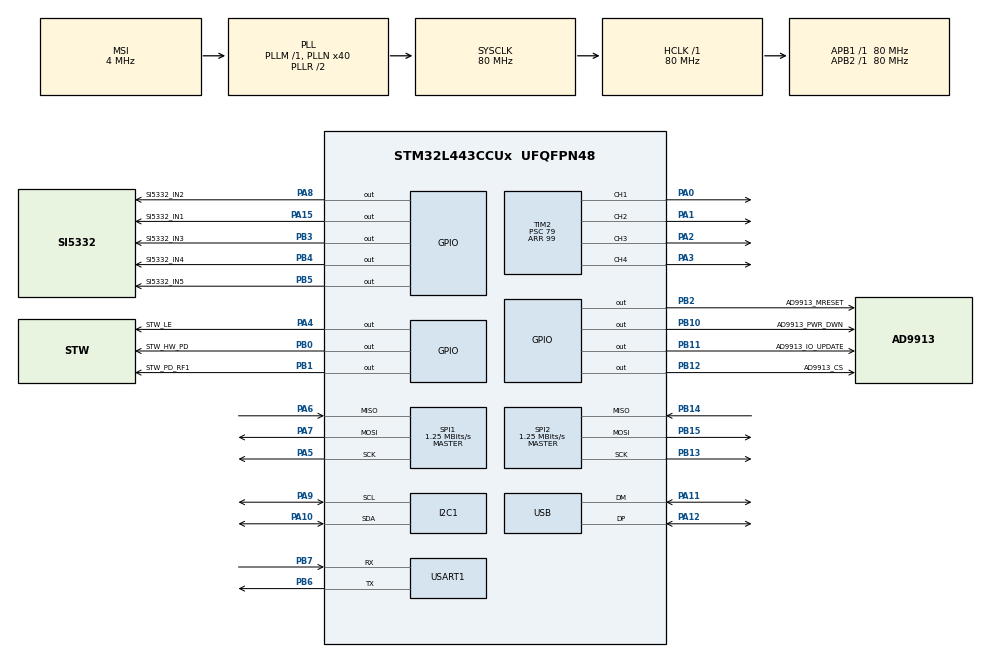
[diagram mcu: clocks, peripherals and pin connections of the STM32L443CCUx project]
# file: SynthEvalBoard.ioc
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FREERTOS.MEMORY_ALLOCATION=1
FREERTOS.Tasks01=defaultTask,0,4096,StartDefaultTask,Default,NULL,Static,defaultTaskBuffer,defaultTaskControlBlock
Mcu.Family=STM32L4
Mcu.Name=STM32L443CCUx
Mcu.Package=UFQFPN48
NVIC.PriorityGroup=NVIC_PRIORITYGROUP_4
NVIC.TIM7_IRQn=true\:0\:0\:false\:false\:true\:false\:false\:true
NVIC.TimeBase=TIM7_IRQn
NVIC.TimeBaseIP=TIM7
PA0.Signal=S_TIM2_CH1
PA1.Signal=S_TIM2_CH2
PA10.Mode=I2C
PA10.Signal=I2C1_SDA
PA11.Mode=Device
PA11.Signal=USB_DM
PA12.Mode=Device
PA12.Signal=USB_DP
PA13\ (JTMS-SWDIO).Mode=Serial_Wire
PA13\ (JTMS-SWDIO).Signal=SYS_JTMS-SWDIO
PA14\ (JTCK-SWCLK).Mode=Serial_Wire
PA14\ (JTCK-SWCLK).Signal=SYS_JTCK-SWCLK
PA15\ (JTDI).GPIO_Label=SI5332_IN1
PA15\ (JTDI).Signal=GPIO_Output
PA2.Signal=S_TIM2_CH3
PA3.Signal=S_TIM2_CH4
PA4.GPIO_Label=STW_LE
PA4.Signal=GPIO_Output
PA5.Mode=Full_Duplex_Master
PA5.Signal=SPI1_SCK
PA6.GPIO_PuPd=GPIO_PULLUP
PA6.Mode=Full_Duplex_Master
PA6.Signal=SPI1_MISO
PA7.Mode=Full_Duplex_Master
PA7.Signal=SPI1_MOSI
PA8.GPIO_Label=SI5332_IN2
PA8.Signal=GPIO_Output
PA9.Mode=I2C
PA9.Signal=I2C1_SCL
PB0.GPIO_Label=STW_HW_PD
PB0.Signal=GPIO_Output
PB1.GPIO_Label=STW_PD_RF1
PB1.Signal=GPIO_Output
PB10.GPIO_Label=AD9913_PWR_DWN
PB10.Signal=GPIO_Output
PB11.GPIO_Label=AD9913_IO_UPDATE
PB11.Signal=GPIO_Output
PB12.GPIO_Label=AD9913_CS
PB12.Signal=GPIO_Output
PB13.Mode=Full_Duplex_Master
PB13.Signal=SPI2_SCK
PB14.Mode=Full_Duplex_Master
PB14.Signal=SPI2_MISO
PB15.Mode=Full_Duplex_Master
PB15.Signal=SPI2_MOSI
PB2.GPIO_Label=AD9913_MRESET
PB2.Signal=GPIO_Output
PB3\ (JTDO-TRACESWO).GPIO_Label=SI5332_IN3
PB3\ (JTDO-TRACESWO).Signal=GPIO_Output
PB4\ (NJTRST).GPIO_Label=SI5332_IN4
PB4\ (NJTRST).Signal=GPIO_Output
PB5.GPIO_Label=SI5332_IN5
PB5.Signal=GPIO_Output
PB6.Mode=Asynchronous
PB6.Signal=USART1_TX
PB7.Mode=Asynchronous
PB7.Signal=USART1_RX
ProjectManager.HeapSize=0x200
ProjectManager.StackSize=0x400
ProjectManager.TargetToolchain=SW4STM32
RCC.ADCFreq_Value=48000000
RCC.AHBFreq_Value=80000000
RCC.APB1Freq_Value=80000000
RCC.APB1TimFreq_Value=80000000
RCC.APB2Freq_Value=80000000
RCC.APB2TimFreq_Value=80000000
RCC.CortexFreq_Value=80000000
RCC.HCLKFreq_Value=80000000
RCC.HSE_VALUE=8000000
RCC.HSI48_VALUE=48000000
RCC.HSI_VALUE=16000000
RCC.LSE_VALUE=32768
RCC.MSI_VALUE=4000000
RCC.PLLN=40
RCC.PLLSAI1N=24
RCC.SYSCLKFreq_VALUE=80000000
RCC.SYSCLKSource=RCC_SYSCLKSOURCE_PLLCLK
RCC.USBFreq_Value=48000000
RCC.VCOOutputFreq_Value=160000000
SH.S_TIM2_CH1.0=TIM2_CH1,PWM Generation1 CH1
SH.S_TIM2_CH2.0=TIM2_CH2,PWM Generation2 CH2
SH.S_TIM2_CH3.0=TIM2_CH3,PWM Generation3 CH3
SH.S_TIM2_CH4.0=TIM2_CH4,PWM Generation4 CH4
SPI1.BaudRatePrescaler=SPI_BAUDRATEPRESCALER_64
SPI1.CLKPhase=SPI_PHASE_1EDGE
SPI1.CLKPolarity=SPI_POLARITY_LOW
SPI1.CalculateBaudRate=1.25 MBits/s
SPI1.DataSize=SPI_DATASIZE_8BIT
SPI1.Direction=SPI_DIRECTION_2LINES
SPI1.Mode=SPI_MODE_MASTER
SPI1.VirtualType=VM_MASTER
SPI2.BaudRatePrescaler=SPI_BAUDRATEPRESCALER_64
SPI2.CalculateBaudRate=1.25 MBits/s
SPI2.DataSize=SPI_DATASIZE_8BIT
SPI2.Direction=SPI_DIRECTION_2LINES
SPI2.Mode=SPI_MODE_MASTER
SPI2.VirtualType=VM_MASTER
TIM2.Channel-PWM\ Generation1\ CH1=TIM_CHANNEL_1
TIM2.Channel-PWM\ Generation2\ CH2=TIM_CHANNEL_2
TIM2.Channel-PWM\ Generation3\ CH3=TIM_CHANNEL_3
TIM2.Channel-PWM\ Generation4\ CH4=TIM_CHANNEL_4
TIM2.Period=99
TIM2.Prescaler=79
USART1.VirtualMode-Asynchronous=VM_ASYNC
VP_FREERTOS_VS_CMSIS_V1.Mode=CMSIS_V1
VP_SYS_VS_tim7.Mode=TIM7
VP_TIM2_VS_ClockSourceINT.Mode=Internal
board=custom

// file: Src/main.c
/* USER CODE BEGIN Header */
/**
  ******************************************************************************
  * @file           : main.c
  * @brief          : Main program body
  ******************************************************************************
  * @attention
  *
  * <h2><center>&copy; Copyright (c) 2021 STMicroelectronics.
  * All rights reserved.</center></h2>
  *
  * This software component is licensed by ST under Ultimate Liberty license
  * SLA0044, the "License"; You may not use this file except in compliance with
  * the License. You may obtain a copy of the License at:
  *                             www.st.com/SLA0044
  *
  ******************************************************************************
  */
/* USER CODE END Header */

#include "main.h"
#include "cmsis_os.h"

I2C_HandleTypeDef hi2c1;

SPI_HandleTypeDef hspi1;
SPI_HandleTypeDef hspi2;

TIM_HandleTypeDef htim2;

UART_HandleTypeDef huart1;

PCD_HandleTypeDef hpcd_USB_FS;

osThreadId defaultTaskHandle;
uint32_t defaultTaskBuffer[ 4096 ];
osStaticThreadDef_t defaultTaskControlBlock;

void SystemClock_Config(void);
static void MX_GPIO_Init(void);
static void MX_I2C1_Init(void);
static void MX_SPI1_Init(void);
static void MX_SPI2_Init(void);
static void MX_USART1_UART_Init(void);
static void MX_TIM2_Init(void);
static void MX_USB_PCD_Init(void);
void StartDefaultTask(void const * argument);

int main(void)
{

  /* MCU Configuration--------------------------------------------------------*/

  /* Reset of all peripherals, Initializes the Flash interface and the Systick. */
  HAL_Init();

  /* Configure the system clock */
  SystemClock_Config();

  /* Initialize all configured peripherals */
  MX_GPIO_Init();
  MX_I2C1_Init();
  MX_SPI1_Init();
  MX_SPI2_Init();
  MX_USART1_UART_Init();
  MX_TIM2_Init();
  MX_USB_PCD_Init();

  /* Create the thread(s) */
  /* definition and creation of defaultTask */
  osThreadStaticDef(defaultTask, StartDefaultTask, osPriorityNormal, 0, 4096, defaultTaskBuffer, &defaultTaskControlBlock);
  defaultTaskHandle = osThreadCreate(osThread(defaultTask), NULL);

  /* Start scheduler */
  osKernelStart();

  /* We should never get here as control is now taken by the scheduler */

  /* Infinite loop */
  while (1)
  {

  }
}

void SystemClock_Config(void)
{
  RCC_OscInitTypeDef RCC_OscInitStruct = {0};
  RCC_ClkInitTypeDef RCC_ClkInitStruct = {0};
  RCC_PeriphCLKInitTypeDef PeriphClkInit = {0};

  /** Initializes the CPU, AHB and APB busses clocks
  */
  RCC_OscInitStruct.OscillatorType = RCC_OSCILLATORTYPE_MSI;
  RCC_OscInitStruct.MSIState = RCC_MSI_ON;
  RCC_OscInitStruct.MSICalibrationValue = 0;
  RCC_OscInitStruct.MSIClockRange = RCC_MSIRANGE_6;
  RCC_OscInitStruct.PLL.PLLState = RCC_PLL_ON;
  RCC_OscInitStruct.PLL.PLLSource = RCC_PLLSOURCE_MSI;
  RCC_OscInitStruct.PLL.PLLM = 1;
  RCC_OscInitStruct.PLL.PLLN = 40;
  RCC_OscInitStruct.PLL.PLLP = RCC_PLLP_DIV7;
  RCC_OscInitStruct.PLL.PLLQ = RCC_PLLQ_DIV2;
  RCC_OscInitStruct.PLL.PLLR = RCC_PLLR_DIV2;
  if (HAL_RCC_OscConfig(&RCC_OscInitStruct) != HAL_OK)
  {
    Error_Handler();
  }
  /** Initializes the CPU, AHB and APB busses clocks
  */
  RCC_ClkInitStruct.ClockType = RCC_CLOCKTYPE_HCLK|RCC_CLOCKTYPE_SYSCLK
                              |RCC_CLOCKTYPE_PCLK1|RCC_CLOCKTYPE_PCLK2;
  RCC_ClkInitStruct.SYSCLKSource = RCC_SYSCLKSOURCE_PLLCLK;
  RCC_ClkInitStruct.AHBCLKDivider = RCC_SYSCLK_DIV1;
  RCC_ClkInitStruct.APB1CLKDivider = RCC_HCLK_DIV1;
  RCC_ClkInitStruct.APB2CLKDivider = RCC_HCLK_DIV1;

  if (HAL_RCC_ClockConfig(&RCC_ClkInitStruct, FLASH_LATENCY_4) != HAL_OK)
  {
    Error_Handler();
  }
  PeriphClkInit.PeriphClockSelection = RCC_PERIPHCLK_USART1|RCC_PERIPHCLK_I2C1
                              |RCC_PERIPHCLK_USB;
  PeriphClkInit.Usart1ClockSelection = RCC_USART1CLKSOURCE_PCLK2;
  PeriphClkInit.I2c1ClockSelection = RCC_I2C1CLKSOURCE_PCLK1;
  PeriphClkInit.UsbClockSelection = RCC_USBCLKSOURCE_PLLSAI1;
  PeriphClkInit.PLLSAI1.PLLSAI1Source = RCC_PLLSOURCE_MSI;
  PeriphClkInit.PLLSAI1.PLLSAI1M = 1;
  PeriphClkInit.PLLSAI1.PLLSAI1N = 24;
  PeriphClkInit.PLLSAI1.PLLSAI1P = RCC_PLLP_DIV7;
  PeriphClkInit.PLLSAI1.PLLSAI1Q = RCC_PLLQ_DIV2;
  PeriphClkInit.PLLSAI1.PLLSAI1R = RCC_PLLR_DIV2;
  PeriphClkInit.PLLSAI1.PLLSAI1ClockOut = RCC_PLLSAI1_48M2CLK;
  if (HAL_RCCEx_PeriphCLKConfig(&PeriphClkInit) != HAL_OK)
  {
    Error_Handler();
  }
  /** Configure the main internal regulator output voltage
  */
  if (HAL_PWREx_ControlVoltageScaling(PWR_REGULATOR_VOLTAGE_SCALE1) != HAL_OK)
  {
    Error_Handler();
  }
}

static void MX_I2C1_Init(void)
{

  hi2c1.Instance = I2C1;
  hi2c1.Init.Timing = 0x10909CEC;
  hi2c1.Init.OwnAddress1 = 0;
  hi2c1.Init.AddressingMode = I2C_ADDRESSINGMODE_7BIT;
  hi2c1.Init.DualAddressMode = I2C_DUALADDRESS_DISABLE;
  hi2c1.Init.OwnAddress2 = 0;
  hi2c1.Init.OwnAddress2Masks = I2C_OA2_NOMASK;
  hi2c1.Init.GeneralCallMode = I2C_GENERALCALL_DISABLE;
  hi2c1.Init.NoStretchMode = I2C_NOSTRETCH_DISABLE;
  if (HAL_I2C_Init(&hi2c1) != HAL_OK)
  {
    Error_Handler();
  }
  /** Configure Analogue filter
  */
  if (HAL_I2CEx_ConfigAnalogFilter(&hi2c1, I2C_ANALOGFILTER_ENABLE) != HAL_OK)
  {
    Error_Handler();
  }
  /** Configure Digital filter
  */
  if (HAL_I2CEx_ConfigDigitalFilter(&hi2c1, 0) != HAL_OK)
  {
    Error_Handler();
  }

}

static void MX_SPI1_Init(void)
{

  /* SPI1 parameter configuration*/
  hspi1.Instance = SPI1;
  hspi1.Init.Mode = SPI_MODE_MASTER;
  hspi1.Init.Direction = SPI_DIRECTION_2LINES;
  hspi1.Init.DataSize = SPI_DATASIZE_8BIT;
  hspi1.Init.CLKPolarity = SPI_POLARITY_LOW;
  hspi1.Init.CLKPhase = SPI_PHASE_1EDGE;
  hspi1.Init.NSS = SPI_NSS_SOFT;
  hspi1.Init.BaudRatePrescaler = SPI_BAUDRATEPRESCALER_64;
  hspi1.Init.FirstBit = SPI_FIRSTBIT_MSB;
  hspi1.Init.TIMode = SPI_TIMODE_DISABLE;
  hspi1.Init.CRCCalculation = SPI_CRCCALCULATION_DISABLE;
  hspi1.Init.CRCPolynomial = 7;
  hspi1.Init.CRCLength = SPI_CRC_LENGTH_DATASIZE;
  hspi1.Init.NSSPMode = SPI_NSS_PULSE_ENABLE;
  if (HAL_SPI_Init(&hspi1) != HAL_OK)
  {
    Error_Handler();
  }

}

static void MX_SPI2_Init(void)
{

  /* SPI2 parameter configuration*/
  hspi2.Instance = SPI2;
  hspi2.Init.Mode = SPI_MODE_MASTER;
  hspi2.Init.Direction = SPI_DIRECTION_2LINES;
  hspi2.Init.DataSize = SPI_DATASIZE_8BIT;
  hspi2.Init.CLKPolarity = SPI_POLARITY_LOW;
  hspi2.Init.CLKPhase = SPI_PHASE_1EDGE;
  hspi2.Init.NSS = SPI_NSS_SOFT;
  hspi2.Init.BaudRatePrescaler = SPI_BAUDRATEPRESCALER_64;
  hspi2.Init.FirstBit = SPI_FIRSTBIT_MSB;
  hspi2.Init.TIMode = SPI_TIMODE_DISABLE;
  hspi2.Init.CRCCalculation = SPI_CRCCALCULATION_DISABLE;
  hspi2.Init.CRCPolynomial = 7;
  hspi2.Init.CRCLength = SPI_CRC_LENGTH_DATASIZE;
  hspi2.Init.NSSPMode = SPI_NSS_PULSE_ENABLE;
  if (HAL_SPI_Init(&hspi2) != HAL_OK)
  {
    Error_Handler();
  }

}

static void MX_TIM2_Init(void)
{

  TIM_ClockConfigTypeDef sClockSourceConfig = {0};
  TIM_MasterConfigTypeDef sMasterConfig = {0};
  TIM_OC_InitTypeDef sConfigOC = {0};

  htim2.Instance = TIM2;
  htim2.Init.Prescaler = 79;
  htim2.Init.CounterMode = TIM_COUNTERMODE_UP;
  htim2.Init.Period = 99;
  htim2.Init.ClockDivision = TIM_CLOCKDIVISION_DIV1;
  htim2.Init.AutoReloadPreload = TIM_AUTORELOAD_PRELOAD_DISABLE;
  if (HAL_TIM_Base_Init(&htim2) != HAL_OK)
  {
    Error_Handler();
  }
  sClockSourceConfig.ClockSource = TIM_CLOCKSOURCE_INTERNAL;
  if (HAL_TIM_ConfigClockSource(&htim2, &sClockSourceConfig) != HAL_OK)
  {
    Error_Handler();
  }
  if (HAL_TIM_PWM_Init(&htim2) != HAL_OK)
  {
    Error_Handler();
  }
  sMasterConfig.MasterOutputTrigger = TIM_TRGO_RESET;
  sMasterConfig.MasterSlaveMode = TIM_MASTERSLAVEMODE_DISABLE;
  if (HAL_TIMEx_MasterConfigSynchronization(&htim2, &sMasterConfig) != HAL_OK)
  {
    Error_Handler();
  }
  sConfigOC.OCMode = TIM_OCMODE_PWM1;
  sConfigOC.Pulse = 0;
  sConfigOC.OCPolarity = TIM_OCPOLARITY_HIGH;
  sConfigOC.OCFastMode = TIM_OCFAST_DISABLE;
  if (HAL_TIM_PWM_ConfigChannel(&htim2, &sConfigOC, TIM_CHANNEL_1) != HAL_OK)
  {
    Error_Handler();
  }
  if (HAL_TIM_PWM_ConfigChannel(&htim2, &sConfigOC, TIM_CHANNEL_2) != HAL_OK)
  {
    Error_Handler();
  }
  if (HAL_TIM_PWM_ConfigChannel(&htim2, &sConfigOC, TIM_CHANNEL_3) != HAL_OK)
  {
    Error_Handler();
  }
  if (HAL_TIM_PWM_ConfigChannel(&htim2, &sConfigOC, TIM_CHANNEL_4) != HAL_OK)
  {
    Error_Handler();
  }
  HAL_TIM_MspPostInit(&htim2);

}

static void MX_USART1_UART_Init(void)
{

  huart1.Instance = USART1;
  huart1.Init.BaudRate = 115200;
  huart1.Init.WordLength = UART_WORDLENGTH_8B;
  huart1.Init.StopBits = UART_STOPBITS_1;
  huart1.Init.Parity = UART_PARITY_NONE;
  huart1.Init.Mode = UART_MODE_TX_RX;
  huart1.Init.HwFlowCtl = UART_HWCONTROL_NONE;
  huart1.Init.OverSampling = UART_OVERSAMPLING_16;
  huart1.Init.OneBitSampling = UART_ONE_BIT_SAMPLE_DISABLE;
  huart1.AdvancedInit.AdvFeatureInit = UART_ADVFEATURE_NO_INIT;
  if (HAL_UART_Init(&huart1) != HAL_OK)
  {
    Error_Handler();
  }

}

static void MX_USB_PCD_Init(void)
{

  /* USER CODE BEGIN USB_Init 0 */
	  /* Enable USB power on Pwrctrl CR2 register. */
	  HAL_PWREx_EnableVddUSB();
  /* USER CODE END USB_Init 0 */

  hpcd_USB_FS.Instance = USB;
  hpcd_USB_FS.Init.dev_endpoints = 8;
  hpcd_USB_FS.Init.speed = PCD_SPEED_FULL;
  hpcd_USB_FS.Init.phy_itface = PCD_PHY_EMBEDDED;
  hpcd_USB_FS.Init.Sof_enable = DISABLE;
  hpcd_USB_FS.Init.low_power_enable = DISABLE;
  hpcd_USB_FS.Init.lpm_enable = DISABLE;
  hpcd_USB_FS.Init.battery_charging_enable = DISABLE;
  if (HAL_PCD_Init(&hpcd_USB_FS) != HAL_OK)
  {
    Error_Handler();
  }

}

static void MX_GPIO_Init(void)
{
  GPIO_InitTypeDef GPIO_InitStruct = {0};

  /* GPIO Ports Clock Enable */
  __HAL_RCC_GPIOA_CLK_ENABLE();
  __HAL_RCC_GPIOB_CLK_ENABLE();

  /*Configure GPIO pin Output Level */
  HAL_GPIO_WritePin(GPIOA, STW_LE_Pin|SI5332_IN2_Pin|SI5332_IN1_Pin, GPIO_PIN_RESET);

  /*Configure GPIO pin Output Level */
  HAL_GPIO_WritePin(GPIOB, STW_HW_PD_Pin|STW_PD_RF1_Pin|AD9913_MRESET_Pin|AD9913_PWR_DWN_Pin
                          |AD9913_IO_UPDATE_Pin|AD9913_CS_Pin|SI5332_IN3_Pin|SI5332_IN4_Pin
                          |SI5332_IN5_Pin, GPIO_PIN_RESET);

  /*Configure GPIO pins : STW_LE_Pin SI5332_IN2_Pin SI5332_IN1_Pin */
  GPIO_InitStruct.Pin = STW_LE_Pin|SI5332_IN2_Pin|SI5332_IN1_Pin;
  GPIO_InitStruct.Mode = GPIO_MODE_OUTPUT_PP;
  GPIO_InitStruct.Pull = GPIO_NOPULL;
  GPIO_InitStruct.Speed = GPIO_SPEED_FREQ_LOW;
  HAL_GPIO_Init(GPIOA, &GPIO_InitStruct);

  /*Configure GPIO pins : STW_HW_PD_Pin STW_PD_RF1_Pin AD9913_MRESET_Pin AD9913_PWR_DWN_Pin
                           AD9913_IO_UPDATE_Pin AD9913_CS_Pin SI5332_IN3_Pin SI5332_IN4_Pin
                           SI5332_IN5_Pin */
  GPIO_InitStruct.Pin = STW_HW_PD_Pin|STW_PD_RF1_Pin|AD9913_MRESET_Pin|AD9913_PWR_DWN_Pin
                          |AD9913_IO_UPDATE_Pin|AD9913_CS_Pin|SI5332_IN3_Pin|SI5332_IN4_Pin
                          |SI5332_IN5_Pin;
  GPIO_InitStruct.Mode = GPIO_MODE_OUTPUT_PP;
  GPIO_InitStruct.Pull = GPIO_NOPULL;
  GPIO_InitStruct.Speed = GPIO_SPEED_FREQ_LOW;
  HAL_GPIO_Init(GPIOB, &GPIO_InitStruct);

}

/* USER CODE BEGIN 4 */
#include "App.h"
/* USER CODE END 4 */

void StartDefaultTask(void const * argument)
{

  /* USER CODE BEGIN 5 */
  App_Start();
  /* Infinite loop */
  for(;;)
  {
    osDelay(1);
  }
  /* USER CODE END 5 */
}

void HAL_TIM_PeriodElapsedCallback(TIM_HandleTypeDef *htim)
{
  if (htim->Instance == TIM7) {
    HAL_IncTick();
  }
}

void Error_Handler(void)
{
}

/************************ (C) COPYRIGHT STMicroelectronics *****END OF FILE****/

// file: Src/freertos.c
/* USER CODE BEGIN Header */
/**
  ******************************************************************************
  * File Name          : freertos.c
  * Description        : Code for freertos applications
  ******************************************************************************
  * @attention
  *
  * <h2><center>&copy; Copyright (c) 2021 STMicroelectronics.
  * All rights reserved.</center></h2>
  *
  * This software component is licensed by ST under Ultimate Liberty license
  * SLA0044, the "License"; You may not use this file except in compliance with
  * the License. You may obtain a copy of the License at:
  *                             www.st.com/SLA0044
  *
  ******************************************************************************
  */
/* USER CODE END Header */

#include "FreeRTOS.h"
#include "task.h"
#include "main.h"

/* GetIdleTaskMemory prototype (linked to static allocation support) */
void vApplicationGetIdleTaskMemory( StaticTask_t **ppxIdleTaskTCBBuffer, StackType_t **ppxIdleTaskStackBuffer, uint32_t *pulIdleTaskStackSize );

/* USER CODE BEGIN GET_IDLE_TASK_MEMORY */
static StaticTask_t xIdleTaskTCBBuffer;
static StackType_t xIdleStack[configMINIMAL_STACK_SIZE];

void vApplicationGetIdleTaskMemory( StaticTask_t **ppxIdleTaskTCBBuffer, StackType_t **ppxIdleTaskStackBuffer, uint32_t *pulIdleTaskStackSize )
{
  *ppxIdleTaskTCBBuffer = &xIdleTaskTCBBuffer;
  *ppxIdleTaskStackBuffer = &xIdleStack[0];
  *pulIdleTaskStackSize = configMINIMAL_STACK_SIZE;
  /* place for user code */
}
/* USER CODE END GET_IDLE_TASK_MEMORY */

/************************ (C) COPYRIGHT STMicroelectronics *****END OF FILE****/
